# STM32C531xx register map
File version: 1.0
Registers are 32-bit, read-write, reset 0x0 unless marked. A register's access mark holds for its fields unless they carry their own. Offsets are from the block's base; [hi:lo] are bit positions; 'fields as' and 'values as' point back to an identical list.

## EXITHDPLIB_PFUNC — EXITHDPLIB function pointer structure
Base 0x0BF883E0
0x0C JumpHDPLvl2
0x10 JumpHDPLvl3

## WWDG
Base 0x40002C00
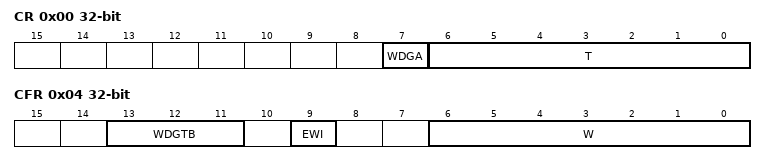
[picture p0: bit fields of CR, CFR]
0x00 CR — WWDG Control register
  [7] WDGA — Activation bit
  [6:0] T — T[6:0] bits (7-Bit counter (MSB to LSB))
0x04 CFR — WWDG Configuration register
  [13:11] WDGTB — WDGTB[2:0] bits (Timer Base)
  [9] EWI — Early Wakeup Interrupt
  [6:0] W — W[6:0] bits (7-bit window value)
0x08 SR — WWDG Status register
  [0] EWIF — Early Wakeup Interrupt Flag

## IWDG
Base 0x40003000
0x00 KR — IWDG Key register
  [15:0] KEY — Key value (write only, read 0000h)
0x04 PR — IWDG Prescaler register
  [3:0] PR — PR[3:0] (Prescaler divider)
0x08 RLR — IWDG Reload register
  [11:0] RL — Watchdog counter reload value
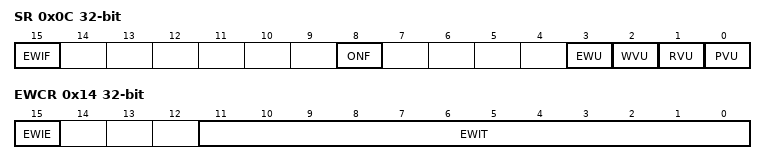
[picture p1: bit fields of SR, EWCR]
0x0C SR ro — IWDG Status register
  [15] EWIF — Watchdog early interrupt flag
  [8] ONF — Watchdog enable flag
  [3] EWU — Watchdog interrupt comparator value update
  [2] WVU — Watchdog counter window value update
  [1] RVU — Watchdog counter reload value update
  [0] PVU — Watchdog prescaler value update
0x10 WINR — IWDG Window register
  [11:0] WIN — Watchdog counter window value
0x14 EWCR — IWDG Early Wakeup register
  [15] EWIE — Watchdog early wakeup comparator value
  [11:0] EWIT — Watchdog early wakeup comparator value
0x18 ICR — IWDG interrupt clear register
  [15] EWIC — Watchdog early interrupt acknowledge

## OPAMP1
Base 0x40003400
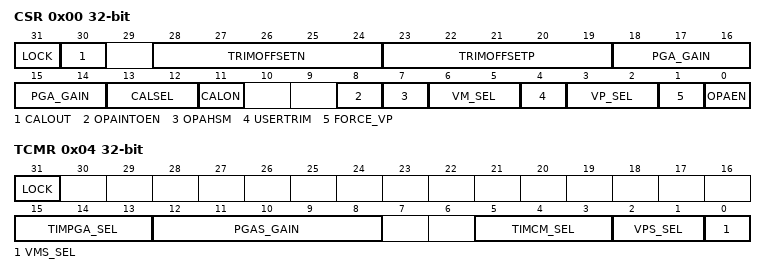
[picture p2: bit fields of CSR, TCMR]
0x00 CSR — OPAMP control/status register
  [31] LOCK — OPAMP_CSR register lock
  [30] CALOUT
  [28:24] TRIMOFFSETN — Trim for NMOS differential pairs
  [23:19] TRIMOFFSETP — Trim for PMOS differential pairs
  [18:14] PGA_GAIN
  [13:12] CALSEL — Calibration selection
  [11] CALON — Calibration mode enable
  [8] OPAINTOEN
  [7] OPAHSM — Operational amplifier high-speed mode
  [6:5] VM_SEL — Inverting input primary selection
  [4] USERTRIM — User trimming enable
  [3:2] VP_SEL — Noninverting input primary selection
  [1] FORCE_VP
  [0] OPAEN — Operational amplifier enable
0x04 TCMR — OPAMP timer-controlled mode register
  [31] LOCK — OPAMP_TCMR register lock
  [15:13] TIMPGA_SEL
  [12:8] PGAS_GAIN
  [5:3] TIMCM_SEL
  [2:1] VPS_SEL
  [0] VMS_SEL

## COMP12_COMMON
Base 0x40004000
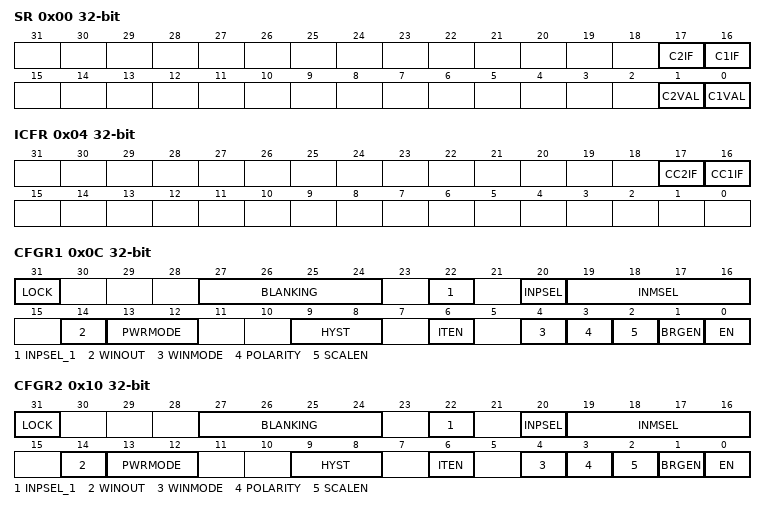
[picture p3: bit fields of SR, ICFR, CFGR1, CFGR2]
0x00 SR ro — Comparator status register
  [17] C2IF, [16] C1IF, [1] C2VAL, [0] C1VAL
0x04 ICFR — Comparator interrupt clear flag register
  [17] CC2IF, [16] CC1IF
0x0C CFGR1 — COMP control and status register located in register of comparator instance odd, used for bits common to several COMP instances
  [31] LOCK — Comparator lock
  [27:24] BLANKING — Comparator blanking source selection
  [22] INPSEL_1 — Comparator input plus selection
  [20] INPSEL — Comparator input plus selection
  [19:16] INMSEL — Comparator input minus selection
  [14] WINOUT — Pair of comparators window output level. Bit intended to be used with COMP common instance (COMP_Common_TypeDef)
  [13:12] PWRMODE — Comparator power mode selection
  [9:8] HYST — Comparator hysteresis selection
  [6] ITEN — Comparator interrupt enable
  [4] WINMODE — Pair of comparators window mode. Bit intended to be used with COMP common instance (COMP_Common_TypeDef)
  [3] POLARITY — Comparator polarity selection
  [2] SCALEN — Comparator voltage scaler enable
  [1] BRGEN — Comparator scaler bridge enable
  [0] EN — Comparator enable
0x10 CFGR2 — COMP control and status register located in register of comparator instance even, used for bits common to several COMP instances
  fields as CFGR1

## COMP1 — Comparator
Base 0x4000400C
Same registers: COMP2 0x40004010
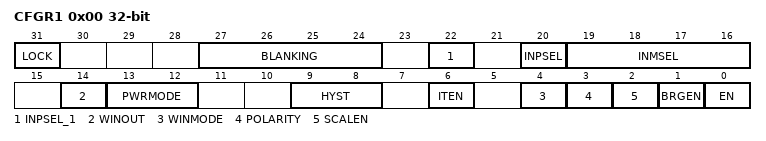
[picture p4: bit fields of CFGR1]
0x00 CFGR1 — Comparator configuration register 1
  [31] LOCK — Comparator lock
  [27:24] BLANKING — Comparator blanking source selection
  [22] INPSEL_1 — Comparator input plus selection
  [20] INPSEL — Comparator input plus selection
  [19:16] INMSEL — Comparator input minus selection
  [14] WINOUT — Pair of comparators window output level. Bit intended to be used with COMP common instance (COMP_Common_TypeDef)
  [13:12] PWRMODE — Comparator power mode selection
  [9:8] HYST — Comparator hysteresis selection
  [6] ITEN — Comparator interrupt enable
  [4] WINMODE — Pair of comparators window mode. Bit intended to be used with COMP common instance (COMP_Common_TypeDef)
  [3] POLARITY — Comparator polarity selection
  [2] SCALEN — Comparator voltage scaler enable
  [1] BRGEN — Comparator scaler bridge enable
  [0] EN — Comparator enable
